# Uchip_regmap0 register map
File version: 1.0.0
Registers are 8-bit, read-write, reset 0x0 unless marked. A register's access mark holds for its fields unless they carry their own. Offsets are from the block's base; lines under a group give offsets from that group; [hi:lo] are bit positions; {n}, {i} and the like mark numbered series; 'fields as' and 'values as' point back to an identical list; <NAME> marks a mode.

## Memory map
0x00000000 CSR size 0x80

## CSR
Base 0x00000000
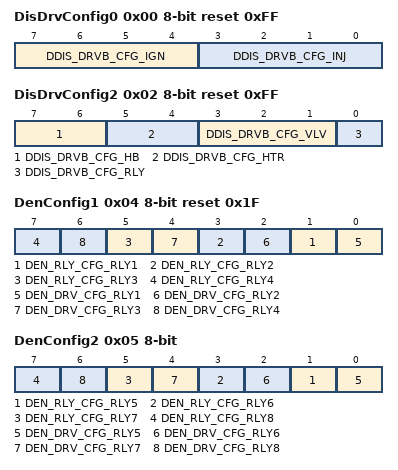
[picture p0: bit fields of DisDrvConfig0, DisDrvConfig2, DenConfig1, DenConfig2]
0x00 DisDrvConfig0 reset 0xFF — Настройка чувствительности силовых драйверов к DIS_DRVb - INJ[4:1], IGN[4:1]
  [7:4] DDIS_DRVB_CFG_IGN — Для IGN[4:1]: 0 - силовой драйвер не отключается при DIS_DRVb=0, 1 - силовой драйвер отключается при DIS_DRVb=0
  [3:0] DDIS_DRVB_CFG_INJ — Для INJ[4:1]: 0 - силовой драйвер не отключается при DIS_DRVb=0, 1 - силовой драйвер отключается при DIS_DRVb=0
0x01 DisDrvConfig1 reset 0xFF — Настройка чувствительности силовых драйверов к DIS_DRVb - RLY[8:1]
  [7:0] DDIS_DRVB_CFG_RLY — Для RLY[8:1]: 0 - силовой драйвер не отключается при DIS_DRVb=0 1 - силовой драйвер отключается при DIS_DRVb=0
0x02 DisDrvConfig2 reset 0xFF — Настройка чувствительности силовых драйверов к DIS_DRVb - RLY[9], VLV[3:1], HTR[2:1], HB[2:1]
  [7:6] DDIS_DRVB_CFG_HB — Для HB[2:1]: 0 - силовой драйвер не отключается при DIS_DRVb=0 1 - силовой драйвер отключается при DIS_DRVb=0
  [5:4] DDIS_DRVB_CFG_HTR — Для HTR[2:1]: 0 - силовой драйвер не отключается при DIS_DRVb=0 1 - силовой драйвер отключается при DIS_DRVb=0
  [3:1] DDIS_DRVB_CFG_VLV — Для VLV[3:1]: 0 - силовой драйвер не отключается при DIS_DRVb=0 1 - силовой драйвер отключается при DIS_DRVb=0
  [0] DDIS_DRVB_CFG_RLY — Для RLY[9]: 0 - силовой драйвер не отключается при DIS_DRVb=0 1 - силовой драйвер отключается при DIS_DRVb=0
0x03 DenConfig0 reset 0xF — Настройка чувствительности силовых драйверов к EN_DRV - IGN[4:1]
  [3:0] DEN_DRV_CFG_IGN — Для IGN[4:1]: 0 - силовой драйвер не отключается при EN_DRV=0 1 - силовой драйвер отключается при EN_DRV=0
0x04 DenConfig1 reset 0x1F — Настройка чувствительности силовых драйвер к EN_DRV и EN_RLY12 - RLY[4:1]
  [2n-1] DEN_RLY_CFG_RLY{n} (n=1..4) — Для RLY[{n}]: 0 - силовой драйвер не отключается при EN_RLY12=0 1 - силовой драйвер отключается при EN_RLY12=0
  [2n-2] DEN_DRV_CFG_RLY{n} (n=1..4) — Для RLY[{n}]: 0 - силовой драйвер не отключается при EN_DRV=0 1 - силовой драйвер отключается при EN_DRV=0
0x05 DenConfig2 — Настройка чувствительности силовых драйвер к EN_DRV и EN_RLY12 - RLY[8:5]
  [2n-9] DEN_RLY_CFG_RLY{n} (n=5..8) — Для RLY[{n}]: 0 - силовой драйвер не отключается при EN_RLY12=0 1 - силовой драйвер отключается при EN_RLY12=0
  [2n-10] DEN_DRV_CFG_RLY{n} (n=5..8) — Для RLY[{n}]: 0 - силовой драйвер не отключается при EN_DRV=0 1 - силовой драйвер отключается при EN_DRV=0
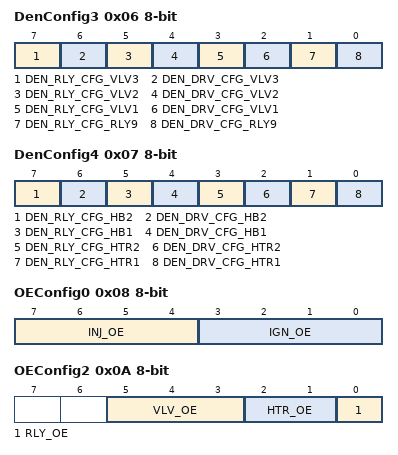
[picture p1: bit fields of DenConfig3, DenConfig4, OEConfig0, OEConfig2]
0x06 DenConfig3 — Настройка чувствительности силовых драйвер к EN_DRV и EN_RLY12 - RLY[9], VLV[3:1]
  [7] DEN_RLY_CFG_VLV3 — Для VLV[3]: 0 - силовой драйвер не отключается при EN_RLY12=0 1 - силовой драйвер отключается при EN_RLY12=0
  [6] DEN_DRV_CFG_VLV3 — Для VLV[3]: 0 - силовой драйвер не отключается при EN_DRV=0 1 - силовой драйвер отключается при EN_DRV=0
  [5] DEN_RLY_CFG_VLV2 — Для VLV[2]: 0 - силовой драйвер не отключается при EN_RLY12=0 1 - силовой драйвер отключается при EN_RLY12=0
  [4] DEN_DRV_CFG_VLV2 — Для VLV[2]: 0 - силовой драйвер не отключается при EN_DRV=0 1 - силовой драйвер отключается при EN_DRV=0
  [3] DEN_RLY_CFG_VLV1 — Для VLV[1]: 0 - силовой драйвер не отключается при EN_RLY12=0 1 - силовой драйвер отключается при EN_RLY12=0
  [2] DEN_DRV_CFG_VLV1 — Для VLV[1]: 0 - силовой драйвер не отключается при EN_DRV=0 1 - силовой драйвер отключается при EN_DRV=0
  [1] DEN_RLY_CFG_RLY9 — Для RLY[9]: 0 - силовой драйвер не отключается при EN_RLY12=0 1 - силовой драйвер отключается при EN_RLY12=0
  [0] DEN_DRV_CFG_RLY9 — Для RLY[9]: 0 - силовой драйвер не отключается при EN_DRV=0 1 - силовой драйвер отключается при EN_DRV=0
0x07 DenConfig4 — Настройка чувствительности силовых драйверов к EN_DRV и EN_RLY12 - HTR[2:1], HB[2:1]
  [7] DEN_RLY_CFG_HB2 — Для HB[2]: 0 - силовой драйвер не отключается при EN_RLY12=0 1 - силовой драйвер отключается при EN_RLY12=0
  [6] DEN_DRV_CFG_HB2 — Для HB[2]: 0 - силовой драйвер не отключается при EN_DRV=0 1 - силовой драйвер отключается при EN_DRV=0
  [5] DEN_RLY_CFG_HB1 — Для HB[1]: 0 - силовой драйвер не отключается при EN_RLY12=0 1 - силовой драйвер отключается при EN_RLY12=0
  [4] DEN_DRV_CFG_HB1 — Для HB[1]: 0 - силовой драйвер не отключается при EN_DRV=0 1 - силовой драйвер отключается при EN_DRV=0
  [3] DEN_RLY_CFG_HTR2 — Для HTR[2]: 0 - силовой драйвер не отключается при EN_RLY12=0 1 - силовой драйвер отключается при EN_RLY12=0
  [2] DEN_DRV_CFG_HTR2 — Для HTR[2]: 0 - силовой драйвер не отключается при EN_DRV=0 1 - силовой драйвер отключается при EN_DRV=0
  [1] DEN_RLY_CFG_HTR1 — Для HTR[1]: 0 - силовой драйвер не отключается при EN_RLY12=0 1 - силовой драйвер отключается при EN_RLY12=0
  [0] DEN_DRV_CFG_HTR1 — Для HTR[1]: 0 - силовой драйвер не отключается при EN_DRV=0 1 - силовой драйвер отключается при EN_DRV=0
0x08 OEConfig0 — Активация управления силовыми драйверами - IGN[4:1], INJ[4:1]
  [7:4] INJ_OE — Для INJ[4:1]: "0" - управление деактивировано "1" - управление активировано
  [3:0] IGN_OE — Для IGN[4:1]: 0 - управление деактивировано 1 - управление активировано
0x09 OEConfig1 — Активация управления силовыми драйверами - RLY[8:1]
  [7:0] RLY_OE — Для RLY[8:1]: 0 - управление деактивировано 1 - управление активировано
0x0A OEConfig2 — Активация управления силовыми драйверами - RLY[9], HTR[2:1], VLV[3:1]
  [5:3] VLV_OE — Для VLV[3:1]: 0 - управление деактивировано 1 - управление активировано
  [2:1] HTR_OE — Для HTR[2:1]: "0" - управление деактивировано "1" - управление активировано
  [0] RLY_OE — Для RLY[9]: 0 - управление деактивировано 1 - управление активировано
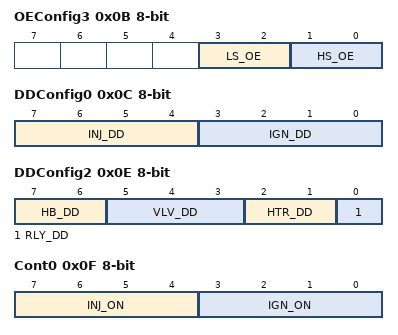
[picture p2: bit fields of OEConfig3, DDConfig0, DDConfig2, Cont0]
0x0B OEConfig3 — Активация\деактивация управления силовыми драйверами - HB[2:1]
  [3:2] LS_OE — Для LS[2:1]: 0 - управление деактивировано 1 - управление активировано
  [1:0] HS_OE — Для HS[2:1]: 0 - управление деактивировано 1 - управление активировано
0x0C DDConfig0 — Выбор способа управления силовыми драйверами - IGN[4:1], INJ[4:1]
  [7:4] INJ_DD — Для INJ[4:1]: 0 - управление осуществляется через SPI 1 - управление осуществляется через Входы Непосредственного Управления
  [3:0] IGN_DD — Для IGN[4:1]: 0 - управление осуществляется через SPI 1 - управление осуществляется через Входы Непосредственного Управления
0x0D DDConfig1 — Выбор способа управления силовыми драйверами - RLY[8:1]
  [7:0] RLY_DD — Для RLY[8:1]: 0 - управление осуществляется через SPI 1 - управление осуществляется через Входы Непосредственного Управления
0x0E DDConfig2 — Выбор способа управления силовыми драйверами - RLY[9], HTR[2:1], VLV[3:1], HB[2:1]
  [7:6] HB_DD — Для HB[2:1]: "0" - управление осуществляется через SPI "1" - управление осуществляется через Входы Непосредственного Управления
  [5:3] VLV_DD — Для VLV[3:1]: 0 - управление осуществляется через SPI 1 - управление осуществляется через Входы Непосредственного Управления
  [2:1] HTR_DD — Для HTR[2:1]: 0 - управление осуществляется через SPI 1 - управление осуществляется через Входы Непосредственного Управления
  [0] RLY_DD — Для RLY[9]: 0 - управление осуществляется через SPI 1 - управление осуществляется через Входы Непосредственного Управления
0x0F Cont0 — SPI-управление ctrl-сигналом силовых драйверов - IGN[4:1], INJ[4:1]
  [7:4] INJ_ON — Для INJ[4:1]: "0" - силовой драйвер ВЫКЛ. "1" - силовой драйвер ВКЛ.
  [3:0] IGN_ON — Для IGN[4:1]: 0 - силовой драйвер ВЫКЛ. 1 - силовой драйвер ВКЛ.
0x10 Cont1 — SPI-управление ctrl-сигналом силовых драйверов - RLY[8:1]
  [7:0] RLY_ON — Для RLY[8:1]: 0 - силовой драйвер ВЫКЛ. 1 - силовой драйвер ВКЛ.
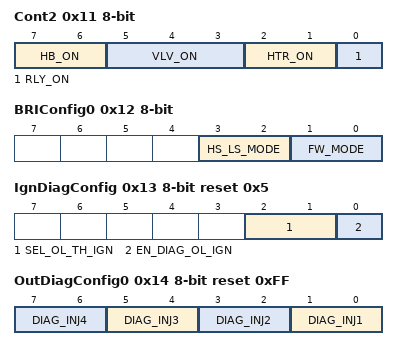
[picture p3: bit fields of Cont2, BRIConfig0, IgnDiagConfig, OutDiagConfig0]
0x11 Cont2 — SPI-управление ctrl-сигналом силовых драйверов - RLY[9], HTR[2:1], VLV[3:1], HB[2:1]
  [7:6] HB_ON — Для HB[2:1]: 0 - силовой драйвер ВЫКЛ. 1 - силовой драйвер ВКЛ.
  [5:3] VLV_ON — Для VLV[3:1]: 0 - силовой драйвер ВЫКЛ. 1 - силовой драйвер ВКЛ.
  [2:1] HTR_ON — Для HTR[2:1]: 0 - силовой драйвер ВЫКЛ. 1 - силовой драйвер ВКЛ.
  [0] RLY_ON — Для RLY[9]: 0 - силовой драйвер ВЫКЛ. 1 - силовой драйвер ВКЛ.
0x12 BRIConfig0 — Настройка работы полумостов - HB[2:1]
  [3:2] HS_LS_MODE — Настройка ctrl-сигнала для HB[2:1]: 0 - ctrl-сигнал идёт на LS 1 - ctrl-сигнал идёт на HS
  [1:0] FW_MODE — Режим Free Wheeling для HB[2:1]: 0 - ВЫКЛ. 1 - ВКЛ.
0x13 IgnDiagConfig reset 0x5 — Настройка OL-диагностики - IGN[4:1]
  [2:1] SEL_OL_TH_IGN — Настройка порога OL-диагностики
  [0] EN_DIAG_OL_IGN — Активация OL-диагностики: 0 - диагностика ВЫКЛ. 1 - диагностика ВКЛ.
0x14 OutDiagConfig0 reset 0xFF — Настройка конфигурации диагностик силовых драйверов - INJ[4:1]
  [2n-1:2n-2] DIAG_INJ{n} (n=1..4) — Для INJ[{n}]: 0x0 - все диагностики ВЫКЛ. 0x1 - все диагностики ВЫКЛ. 0x2 -только SCG/SCB диагностика ВКЛ. 0x3 - SCG/SCB и OL диагностика ВКЛ.
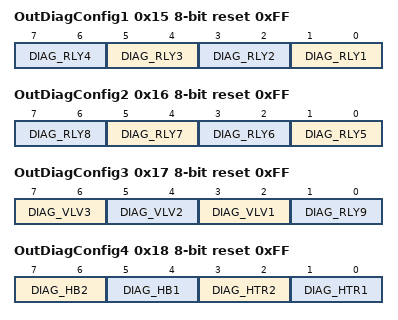
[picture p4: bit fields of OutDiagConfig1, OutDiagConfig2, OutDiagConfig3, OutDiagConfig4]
0x15 OutDiagConfig1 reset 0xFF — Настройка конфигурации диагностик силовых драйверов - RLY[4:1]
  [2n-1:2n-2] DIAG_RLY{n} (n=1..4) — Для RLY[{n}]: 0x0 - все диагностики ВЫКЛ. 0x1 - все диагностики ВЫКЛ. 0x2 -только SCG/SCB диагностика ВКЛ. 0x3 - SCG/SCB и OL диагностика ВКЛ.
0x16 OutDiagConfig2 reset 0xFF — Настройка конфигурации диагностик силовых драйверов - RLY[8:5]
  [2n-9:2n-10] DIAG_RLY{n} (n=5..8) — Для RLY[{n}]: 0x0 - все диагностики ВЫКЛ. 0x1 - все диагностики ВЫКЛ. 0x2 -только SCG/SCB диагностика ВКЛ. 0x3 - SCG/SCB и OL диагностика ВКЛ.
0x17 OutDiagConfig3 reset 0xFF — Настройка конфигурации диагностик силовых драйверов - RLY[9], VLV[3:1]
  [7:6] DIAG_VLV3 — Для VLV[3]: 0x0 - все диагностики ВЫКЛ. 0x1 - все диагностики ВЫКЛ. 0x2 -только SCG/SCB диагностика ВКЛ. 0x3 - SCG/SCB и OL диагностика ВКЛ.
  [5:4] DIAG_VLV2 — Для VLV[2]: 0x0 - все диагностики ВЫКЛ. 0x1 - все диагностики ВЫКЛ. 0x2 -только SCG/SCB диагностика ВКЛ. 0x3 - SCG/SCB и OL диагностика ВКЛ.
  [3:2] DIAG_VLV1 — Для VLV[1]: 0x0 - все диагностики ВЫКЛ. 0x1 - все диагностики ВЫКЛ. 0x2 -только SCG/SCB диагностика ВКЛ. 0x3 - SCG/SCB и OL диагностика ВКЛ.
  [1:0] DIAG_RLY9 — Для RLY[9]: 0x0 - все диагностики ВЫКЛ. 0x1 - все диагностики ВЫКЛ. 0x2 -только SCG/SCB диагностика ВКЛ. 0x3 - SCG/SCB и OL диагностика ВКЛ.
0x18 OutDiagConfig4 reset 0xFF — Настройка конфигурации диагностик силовых драйверов - HTR[2:1], HB[2:1]
  [7:6] DIAG_HB2 — Для HB[2]: 0x0 - все диагностики ВЫКЛ. 0x1 - все диагностики ВЫКЛ. 0x2 -только SCG/SCB диагностика ВКЛ. 0x3 - SCG/SCB и OL диагностика ВКЛ.
  [5:4] DIAG_HB1 — Для HB[1]: 0x0 - все диагностики ВЫКЛ. 0x1 - все диагностики ВЫКЛ. 0x2 -только SCG/SCB диагностика ВКЛ. 0x3 - SCG/SCB и OL диагностика ВКЛ.
  [3:2] DIAG_HTR2 — Для HTR[2]: 0x0 - все диагностики ВЫКЛ. 0x1 - все диагностики ВЫКЛ. 0x2 -только SCG/SCB диагностика ВКЛ. 0x3 - SCG/SCB и OL диагностика ВКЛ.
  [1:0] DIAG_HTR1 — Для HTR[1]: 0x0 - все диагностики ВЫКЛ. 0x1 - все диагностики ВЫКЛ. 0x2 -только SCG/SCB диагностика ВКЛ. 0x3 - SCG/SCB и OL диагностика ВКЛ.
0x19 CurrLimConfig0 — Активация режима ограничения по току силовых драйверов в случае OC - INJ[4:1]
  [3:0] CURR_LIM_INJ — Для INJ[4:1]: 0 - режим ВЫКЛ. 1 - режим ВКЛ.
0x1A CurrLimConfig1 — Активация режима ограничения по току силовых драйверов в случае OC - RLY[8:1]
  [7:0] CURR_LIM_RLY — Для RLY[8:1]: 0 - режим ВЫКЛ. 1 - режим ВКЛ.
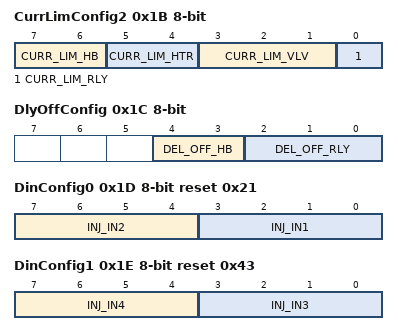
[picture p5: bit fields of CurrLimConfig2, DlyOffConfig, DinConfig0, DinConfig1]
0x1B CurrLimConfig2 — Активация режима ограничения по току силовых драйверов в случае OC - RLY[9], VLV[3:1], HTR[2:1], HB[2:1]
  [7:6] CURR_LIM_HB — Для HB[2:1]: 0 - режим ВЫКЛ. 1 - режим ВКЛ.
  [5:4] CURR_LIM_HTR — Для HTR[2:1]: 0 - режим ВЫКЛ. 1 - режим ВКЛ.
  [3:1] CURR_LIM_VLV — Для VLV[3:1]: 0 - режим ВЫКЛ. 1 - режим ВКЛ.
  [0] CURR_LIM_RLY — Для RLY[9]: 0 - режим ВЫКЛ. 1 - режим ВКЛ.
0x1C DlyOffConfig — Активация режима позднего отключения силовых драйверов в случае VDD5_UV, VDD5_OV, WD_FAIL, RSTb=0
  [4:3] DEL_OFF_HB — Для HB[2:1]: 0 - режим ВЫКЛ. 1 - режим ВКЛ.
  [2:0] DEL_OFF_RLY — Для RLY[3:1]: 0 - режим ВЫКЛ. 1 - режим ВКЛ.
0x1D DinConfig0 reset 0x21 — Выбор Входа Непосредственно Управления для управления силовыми драйверами - INJ[2:1]
  [7:4] INJ_IN2 — Для INJ[2]: 0x1 - IN1, 0x2 - IN2, 0x3 - IN3, 0x4 - IN4, 0x5 - IN5, 0x6 - IN6, 0x7 - IN7, 0x8 - IN8, 0x9 - IN9, 0xA - IN10, 0xB - IN11, 0xC - IN12, 0xD - IN13
  [3:0] INJ_IN1 — Для INJ[1]: 0x1 - IN1, 0x2 - IN2, 0x3 - IN3, 0x4 - IN4, 0x5 - IN5, 0x6 - IN6, 0x7 - IN7, 0x8 - IN8, 0x9 - IN9, 0xA - IN10, 0xB - IN11, 0xC - IN12, 0xD - IN13
0x1E DinConfig1 reset 0x43 — Выбор Входа Непосредственно Управления для управления силовыми драйверами - INJ[4:3]
  [7:4] INJ_IN4 — Для INJ[4]: 0x1 - IN1, 0x2 - IN2, 0x3 - IN3, 0x4 - IN4, 0x5 - IN5, 0x6 - IN6, 0x7 - IN7, 0x8 - IN8, 0x9 - IN9, 0xA - IN10, 0xB - IN11, 0xC - IN12, 0xD - IN13
  [3:0] INJ_IN3 — Для INJ[3]: 0x1 - IN1, 0x2 - IN2, 0x3 - IN3, 0x4 - IN4, 0x5 - IN5, 0x6 - IN6, 0x7 - IN7, 0x8 - IN8, 0x9 - IN9, 0xA - IN10, 0xB - IN11, 0xC - IN12, 0xD - IN13
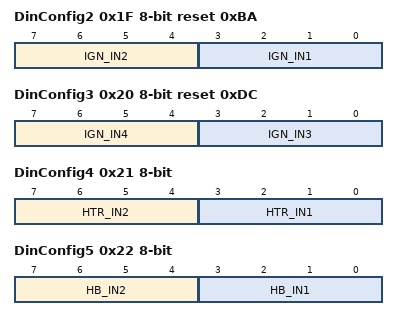
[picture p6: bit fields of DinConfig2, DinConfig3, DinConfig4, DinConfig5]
0x1F DinConfig2 reset 0xBA — Выбор Входа Непосредственно Управления для управления силовыми драйверами - IGN[2:1]
  [7:4] IGN_IN2 — Для IGN[2]: 0x1 - IN1, 0x2 - IN2, 0x3 - IN3, 0x4 - IN4, 0x5 - IN5, 0x6 - IN6, 0x7 - IN7, 0x8 - IN8, 0x9 - IN9, 0xA - IN10, 0xB - IN11, 0xC - IN12, 0xD - IN13
  [3:0] IGN_IN1 — Для IGN[1]: 0x1 - IN1, 0x2 - IN2, 0x3 - IN3, 0x4 - IN4, 0x5 - IN5, 0x6 - IN6, 0x7 - IN7, 0x8 - IN8, 0x9 - IN9, 0xA - IN10, 0xB - IN11, 0xC - IN12, 0xD - IN13
0x20 DinConfig3 reset 0xDC — Выбор Входа Непосредственно Управления для управления силовыми драйверами - IGN[4:3]
  [7:4] IGN_IN4 — Для IGN[4]: 0x1 - IN1, 0x2 - IN2, 0x3 - IN3, 0x4 - IN4, 0x5 - IN5, 0x6 - IN6, 0x7 - IN7, 0x8 - IN8, 0x9 - IN9, 0xA - IN10, 0xB - IN11, 0xC - IN12, 0xD - IN13
  [3:0] IGN_IN3 — Для IGN[3]: 0x1 - IN1, 0x2 - IN2, 0x3 - IN3, 0x4 - IN4, 0x5 - IN5, 0x6 - IN6, 0x7 - IN7, 0x8 - IN8, 0x9 - IN9, 0xA - IN10, 0xB - IN11, 0xC - IN12, 0xD - IN13
0x21 DinConfig4 — Выбор Входа Непосредственно Управления для управления силовыми драйверами - HTR[2:1]
  [7:4] HTR_IN2 — Для HTR[2]: 0x1 - IN1, 0x2 - IN2, 0x3 - IN3, 0x4 - IN4, 0x5 - IN5, 0x6 - IN6, 0x7 - IN7, 0x8 - IN8, 0x9 - IN9, 0xA - IN10, 0xB - IN11, 0xC - IN12, 0xD - IN13
  [3:0] HTR_IN1 — Для HTR[1]: 0x1 - IN1, 0x2 - IN2, 0x3 - IN3, 0x4 - IN4, 0x5 - IN5, 0x6 - IN6, 0x7 - IN7, 0x8 - IN8, 0x9 - IN9, 0xA - IN10, 0xB - IN11, 0xC - IN12, 0xD - IN13
0x22 DinConfig5 — Выбор Входа Непосредственно Управления для управления силовыми драйверами - HB[2:1]
  [7:4] HB_IN2 — Для HB[2]: 0x1 - IN1, 0x2 - IN2, 0x3 - IN3, 0x4 - IN4, 0x5 - IN5, 0x6 - IN6, 0x7 - IN7, 0x8 - IN8, 0x9 - IN9, 0xA - IN10, 0xB - IN11, 0xC - IN12, 0xD - IN13
  [3:0] HB_IN1 — Для HB[1]: 0x1 - IN1, 0x2 - IN2, 0x3 - IN3, 0x4 - IN4, 0x5 - IN5, 0x6 - IN6, 0x7 - IN7, 0x8 - IN8, 0x9 - IN9, 0xA - IN10, 0xB - IN11, 0xC - IN12, 0xD - IN13
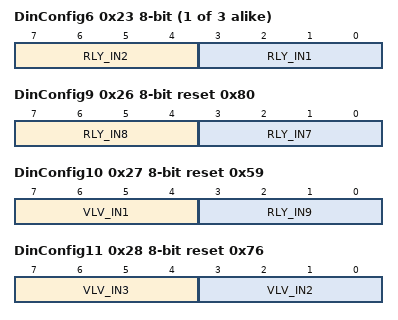
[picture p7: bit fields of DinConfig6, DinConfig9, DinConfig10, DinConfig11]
{0x1D+i} DinConfig{i} (i=6..8) — Выбор Входа Непосредственно Управления для управления силовыми драйверами - RLY[{2i-10}:{2i-11}]
  [7:4] RLY_IN{2i-10} — Для RLY[{2i-10}]: 0x1 - IN1, 0x2 - IN2, 0x3 - IN3, 0x4 - IN4, 0x5 - IN5, 0x6 - IN6, 0x7 - IN7, 0x8 - IN8, 0x9 - IN9, 0xA - IN10, 0xB - IN11, 0xC - IN12, 0xD - IN13
  [3:0] RLY_IN{2i-11} — Для RLY[{2i-11}]: 0x1 - IN1, 0x2 - IN2, 0x3 - IN3, 0x4 - IN4, 0x5 - IN5, 0x6 - IN6, 0x7 - IN7, 0x8 - IN8, 0x9 - IN9, 0xA - IN10, 0xB - IN11, 0xC - IN12, 0xD - IN13
0x26 DinConfig9 reset 0x80 — Выбор Входа Непосредственно Управления для управления силовыми драйверами - RLY[8:7]
  [7:4] RLY_IN8 — Для RLY[8]: 0x1 - IN1, 0x2 - IN2, 0x3 - IN3, 0x4 - IN4, 0x5 - IN5, 0x6 - IN6, 0x7 - IN7, 0x8 - IN8, 0x9 - IN9, 0xA - IN10, 0xB - IN11, 0xC - IN12, 0xD - IN13
  [3:0] RLY_IN7 — Для RLY[7]: 0x1 - IN1, 0x2 - IN2, 0x3 - IN3, 0x4 - IN4, 0x5 - IN5, 0x6 - IN6, 0x7 - IN7, 0x8 - IN8, 0x9 - IN9, 0xA - IN10, 0xB - IN11, 0xC - IN12, 0xD - IN13
0x27 DinConfig10 reset 0x59 — Выбор Входа Непосредственно Управления для управления силовыми драйверами - RLY[9], VLV[1]
  [7:4] VLV_IN1 — Для VLV[1]: 0x1 - IN1, 0x2 - IN2, 0x3 - IN3, 0x4 - IN4, 0x5 - IN5, 0x6 - IN6, 0x7 - IN7, 0x8 - IN8, 0x9 - IN9, 0xA - IN10, 0xB - IN11, 0xC - IN12, 0xD - IN13
  [3:0] RLY_IN9 — Для RLY[9]: 0x1 - IN1, 0x2 - IN2, 0x3 - IN3, 0x4 - IN4, 0x5 - IN5, 0x6 - IN6, 0x7 - IN7, 0x8 - IN8, 0x9 - IN9, 0xA - IN10, 0xB - IN11, 0xC - IN12, 0xD - IN13
0x28 DinConfig11 reset 0x76 — Выбор Входа Непосредственно Управления для управления силовыми драйверами - VLV[3:2]
  [7:4] VLV_IN3 — Для VLV[3]: 0x1 - IN1, 0x2 - IN2, 0x3 - IN3, 0x4 - IN4, 0x5 - IN5, 0x6 - IN6, 0x7 - IN7, 0x8 - IN8, 0x9 - IN9, 0xA - IN10, 0xB - IN11, 0xC - IN12, 0xD - IN13
  [3:0] VLV_IN2 — Для VLV[2]: 0x1 - IN1, 0x2 - IN2, 0x3 - IN3, 0x4 - IN4, 0x5 - IN5, 0x6 - IN6, 0x7 - IN7, 0x8 - IN8, 0x9 - IN9, 0xA - IN10, 0xB - IN11, 0xC - IN12, 0xD - IN13
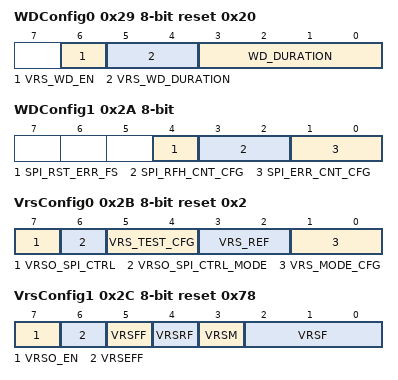
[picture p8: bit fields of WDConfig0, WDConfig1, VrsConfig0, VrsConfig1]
0x29 WDConfig0 reset 0x20 — Настройки Сторожевых Таймеров (WatchDog)
  [6] VRS_WD_EN — Активация VRS WatchDog: 0 - ВЫКЛ. 1 - ВКЛ.
  [5:4] VRS_WD_DURATION — Настройка порога VRS WatchDog
  [3:0] WD_DURATION — Настройка длительности ожидания "посылки-ответа" SPI WatchDog
0x2A WDConfig1 — Настройки SPI WatchDog
  [4] SPI_RST_ERR_FS — Настройка порога генерации FAULTb, RSTb: 0 - стандартный порог 1 - уменьшенный в два раза порог
  [3:2] SPI_RFH_CNT_CFG — Настройка порога счетчика успехов: 0x0 - 6 успехов 0x1 - 6 успехов 0x2 - 4 успеха 0x3 - 2 успеха
  [1:0] SPI_ERR_CNT_CFG — Настройка порога счетчика ошибок: 0x0 - 6 ошибок 0x1 - 6 ошибок 0x2 - 4 ошибки 0x3 - 2 ошибки
0x2B VrsConfig0 reset 0x2 — Конфигурация VR Сенсора
  [7] VRSO_SPI_CTRL — Сигнал установки значения на VRS_OUT в режиме прямого управления
  [6] VRSO_SPI_CTRL_MODE — Активация режима прямого управления управления VRS_OUT: 0 - ВЫКЛ. 1 - ВКЛ.
  [5:4] VRS_TEST_CFG — Настройка режима тестирования: 0x0 - все тесты 0x1 - SCG 0x2 - SCB 0x3 - OL
  [3:2] VRS_REF — Настройка значения vrs_ref
  [1:0] VRS_MODE_CFG — Настройка режима vrs_mode: 0x0 - ручной 0x1 - Hall-сенсор 0x2 - автоматический 0x3 - pre diag
0x2C VrsConfig1 reset 0x78 — Конфигурация VR Сенсора
  [7] VRSO_EN — Активация/деактивация VROUT-буфера: 0 - ВЫКЛ. 1 - ВКЛ.
  [6] VRSEFF — Активация/деактивация маскирования по Falling Edge: 0 - ВЫКЛ. 1 - ВКЛ.
  [5] VRSFF — Активация/деактивация фильтрации по Falling Edge: 0 - ВЫКЛ. 1 - ВКЛ.
  [4] VRSRF — Активация/деактивация фильтрации по Rising Edge: 0 - ВЫКЛ. 1 - ВКЛ.
  [3] VRSM — Настройка режима фильтации: 0 - адаптивный 1 - ручной
  [2:0] VRSF — Настройка времени фильтрации в ручном режиме: 0x0 - 2мкс 0x1 - 4мкс 0x2 - 8мкс 0x3 - 16мкс 0x4 - 32мкс 0x5 - 64мкс 0x6 - 128мкс 0x7 - 200мкс
0x2D VrsConfig2 — Конфигурация VR Сенсора
  [6:0] VRS_OL_DIAG — Настройка OL-диагностики VR Сенсора
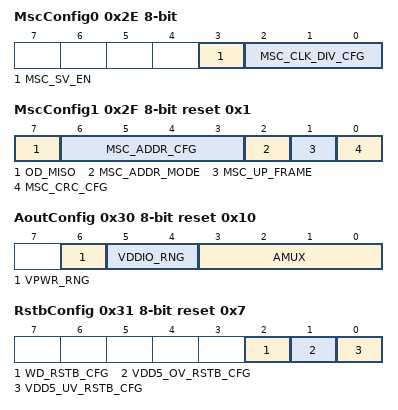
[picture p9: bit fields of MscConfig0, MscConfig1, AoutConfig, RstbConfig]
0x2E MscConfig0 — Конфигурация MSC Интерфейса
  [3] MSC_SV_EN — Активация/деактивация SuperVision функции: 0 - ВЫКЛ. 1 - ВКЛ.
  [2:0] MSC_CLK_DIV_CFG — Настройка делителя частоты SCLK для Upstream-посылок: 0x0 - 64 0x1 - 4 0x2 - 8 0x3 - 16 0x4 - 32 0x5 - 64 0x6 - 128 0x7 - 256
0x2F MscConfig1 reset 0x1 — Конфигурация MSC Интерфейса
  [7] OD_MISO — Активация режима OpenDrain для MSC: 0 - ВЫКЛ. 1 - ВКЛ.
  [6:3] MSC_ADDR_CFG — Значения адресного поля в случае выбора фиксированного адреса
  [2] MSC_ADDR_MODE — Активация режима установки адресного поля: 0 - автоматический подбор 1 - фиксированный MSC_ADDR_CFG
  [1] MSC_UP_FRAME — Настройка типа Upstream кадра: 0 - без адресного поля 1 - с адресным полем
  [0] MSC_CRC_CFG — Тип бита четности: 0 - нечётный 1 - чётный
0x30 AoutConfig reset 0x10 — Конфигурация AOUT буфера
  [6] VPWR_RNG — Настройка порогов VPWR-монитора: 0 - sel_vpwr_ov_th=0 - 12В 1 - sel_vpwr_ov_th=1 - 24В
  [5:4] VDDIO_RNG — Настройка порогов VDDIO-монитора: 0x0 - sel_vddio_uv_th=0, sel_vddio_ov_th=0 - 3.3В 0x1 - sel_vddio_uv_th=0, sel_vddio_ov_th=1 - широкий диапазон 0x2 - sel_vddio_uv_th=1, sel_vddio_ov_th=0 - узкий диапазон 0x3 - sel_vddio_uv_th=1, sel_vddio_ov_th=1 - 5В
  [3:0] AMUX — Настройка AOUT-буфера: 0x0 - en_aout=0 0x1 - en_aout=1, sel_aout_vrs_amp=1 - выводится дифф. напряжения усилителя VRS 0x2 - en_aout=1, sel_aout_vdd5_sns=1 - выводится VDD5 0x3 - en_aout=1, sel_aout_vddio_sns=1 - выводится VDDIO 0x4 - en_aout=1, sel_aout_vpwr_sns=1 - выводится VPWR 0x5 - en_aout=1, sel_aout_vtemp_sns=1 - выводится напряжения температурного датчика any: en_aout=0
0x31 RstbConfig reset 0x7 — Конфигурация сброса цифровой логики
  [2] WD_RSTB_CFG — Сброс цифрвой логики по переполнению WD счетчика ошибок: 0 - reset не происходит 1 - reset происходит
  [1] VDD5_OV_RSTB_CFG — Сброс цифрвой логики по VDD5_OV: 0 - reset не происходит 1 - reset происходит
  [0] VDD5_UV_RSTB_CFG — Сброс цифррвой логики по VDD5_UV: 0 - reset не происходит 1 - reset происходит
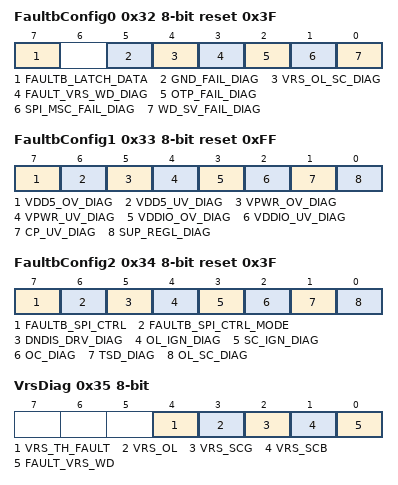
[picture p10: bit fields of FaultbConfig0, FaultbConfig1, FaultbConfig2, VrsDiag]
0x32 FaultbConfig0 reset 0x3F — Конфигурация FAULTb вывода
  [7] FAULTB_LATCH_DATA — Режим репортирования ошибок: 0 - репортируются актуальные ошибки 1 - репортируются ошибки, хранящиеся в диагностических регистрах
  [5] GND_FAIL_DIAG — Настройка реакции FAULTb на ошибки потери земли (AGND/PGND/GNDIO_LOSS): 0 - игнорирурет 1 - репортирует
  [4] VRS_OL_SC_DIAG — Настройка реакции FAULTb на ошибки диагностик VRS (OL, SCG, SCB): 0 - игнорирурет 1 - репортирует
  [3] FAULT_VRS_WD_DIAG — Настройка реакции FAULTb на ошибку по VRS WD: 0 - игнорирурет 1 - репортирует
  [2] OTP_FAIL_DIAG — Настройка реакции FAULTb на OTP-ошибку (ошибка коммуникации OTP, обращение к занятому контроллеру, ошибка чтения OTP, ошибка tm тестов margin off, margin1, margin2, selftest): 0 - игнорирурет 1 - репортирует
  [1] SPI_MSC_FAIL_DIAG — Настройка реакции FAULTb на обращения по SPI/MSC к неверному адресу: 0 - игнорирурет 1 - репортирует
  [0] WD_SV_FAIL_DIAG — Настройка реакции FAULTb на ошибки по WD и SV функциям: 0 - игнорирурет 1 - репортирует
0x33 FaultbConfig1 reset 0xFF — Конфигурация FAULTb вывода
  [7] VDD5_OV_DIAG — Настройка реакции FAULTb на OV по VDD5: 0 - игнорирурет 1 - репортирует
  [6] VDD5_UV_DIAG — Настройка реакции FAULTb на UV по VDD5: 0 - игнорирурет 1 - репортирует
  [5] VPWR_OV_DIAG — Настройка реакции FAULTb на OV по VPWR: 0 - игнорирурет 1 - репортирует
  [4] VPWR_UV_DIAG — Настройка реакции FAULTb на UV по VPWR: 0 - игнорирурет 1 - репортирует
  [3] VDDIO_OV_DIAG — Настройка реакции FAULTb на OV по VDDIO: 0 - игнорирурет 1 - репортирует
  [2] VDDIO_UV_DIAG — Настройка реакции FAULTb на UV по VDDIO: 0 - игнорирурет 1 - репортирует
  [1] CP_UV_DIAG — Настройка реакции FAULTb на UV по CP: 0 - игнорирурет 1 - репортирует
  [0] SUP_REGL_DIAG — Настройка реакции FAULTb на OV/UV по vdig_1p5v, vana_1p5v: 0 - игнорирурет 1 - репортирует
0x34 FaultbConfig2 reset 0x3F — Конфигурация FAULTb вывода
  [7] FAULTB_SPI_CTRL — Значение сигнала FAULTb в случае прямого управления
  [6] FAULTB_SPI_CTRL_MODE — Активация/деактивация режима прямого управления FAULTb: 0 - прямое управление ВЫКЛ. 1 - прямое управление ВКЛ.
  [5] DNDIS_DRV_DIAG — Настройка реакции FAULTb на DIS_DRVb=0: 0 - игнорирурет 1 - репортирует
  [4] OL_IGN_DIAG — Настройка реакции FAULTb на ошибки OL-диагностики для IGN: 0 - игнорирурет 1 - репортирует
  [3] SC_IGN_DIAG — Настройка реакции FAULTb на ошибки SCG/SCB-защиты для IGN: 0 - игнорирурет 1 - репортирует
  [2] OC_DIAG — Настройка реакции FAULTb на ошибки OC-защиты для RLY/INJ/VLV/HTR/HB: 0 - игнорирурет 1 - репортирует
  [1] TSD_DIAG — Настройка реакции FAULTb на ошибки TSD-защиты для RLY/INJ/VLV/HTR/HB/IGN: 0 - игнорирурет 1 - репортирует
  [0] OL_SC_DIAG — Настройка реакции FAULTb на ошибки OL-диагностик для RLY/INJ/VLV/HTR/HB, SCG-диагностик для RLY/INJ/VLV/HTR/HB_LS, SCB-диагностики для HB_HS: 0 - игнорирурет 1 - репортирует
0x35 VrsDiag ro — Диагностический регистр для VR Сенсора
  [4] VRS_TH_FAULT — Нарушение порога компаратора
  [3] VRS_OL — Обрыв нагрузки
  [2] VRS_SCG — КЗ на землю
  [1] VRS_SCB — КЗ на питание
  [0] FAULT_VRS_WD — Многоскратный сбой по VRS WD
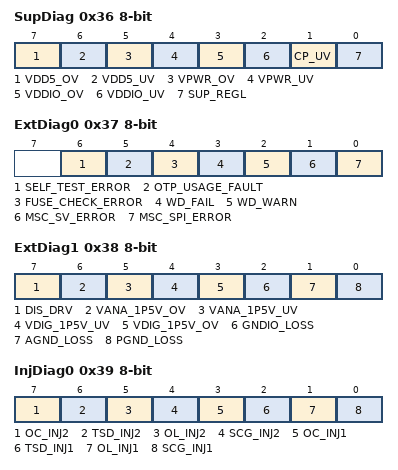
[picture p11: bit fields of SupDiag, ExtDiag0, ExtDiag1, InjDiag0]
0x36 SupDiag ro — Диагностический регистр для Мониторов питаний
  [7] VDD5_OV — OverVoltage по VDD5
  [6] VDD5_UV — UnderVoltage по VDD5
  [5] VPWR_OV — OverVoltage по VPWR
  [4] VPWR_UV — UnderVoltage по VPWR
  [3] VDDIO_OV — OverVoltage по VDDIO
  [2] VDDIO_UV — UnderVoltage по VDDIO
  [1] CP_UV — UnderVoltage по CP
  [0] SUP_REGL — Нарушения по vana_1p5v, vdig_1p5v (см. регистр ExtDiag1)
0x37 ExtDiag0 ro — Диагностический регистр внутренних ошибок цифровых функций
  [6] SELF_TEST_ERROR — Ошибка сравнения данных при тестовых проверках (margin off, margine1, margin2, selftest)
  [5] OTP_USAGE_FAULT — Обращение к занятомму контроллеру или неправльная команда OTP контроллера
  [4] FUSE_CHECK_ERROR — При чтении OTP обнаружены неверные данные
  [3] WD_FAIL — Исчерпан лимит ошибок по WD
  [2] WD_WARN — Предупреждение о наличии множественных нарушений по WD
  [1] MSC_SV_ERROR — Ошибка истечения SuperVision таймера
  [0] MSC_SPI_ERROR — Ошибка обращения по SPI/MSC к неверному адресу
0x38 ExtDiag1 ro — Диагностический регистр внутренних ошибок - потеря земли, OV/UV внутренних регуляторов
  [7] DIS_DRV — Статус DIS_DRVb=0
  [6] VANA_1P5V_OV — Ошибка OverVoltage по vana_1p5v
  [5] VANA_1P5V_UV — Ошибка UnderVoltage по vana_1p5v
  [4] VDIG_1P5V_UV — Ошибка UnderVoltage по vdig_1p5v
  [3] VDIG_1P5V_OV — Ошибка OverVoltage по vdig_1p5v
  [2] GNDIO_LOSS — Ошибка обрыва земли GNDIO
  [1] AGND_LOSS — Ошибка обрыва земли AGND
  [0] PGND_LOSS — Ошибка обрыва земли PGND
0x39 InjDiag0 ro — Диагностический регистр для силовых драйверов - INJ[2:1]
  [7] OC_INJ2 — OC для INJ[2]
  [6] TSD_INJ2 — TSD для INJ[2]
  [5] OL_INJ2 — OL для INJ[2]
  [4] SCG_INJ2 — SCG для INJ[2]
  [3] OC_INJ1 — OC для INJ[1]
  [2] TSD_INJ1 — TSD для INJ[1]
  [1] OL_INJ1 — OL для INJ[1]
  [0] SCG_INJ1 — SCG для INJ[1]
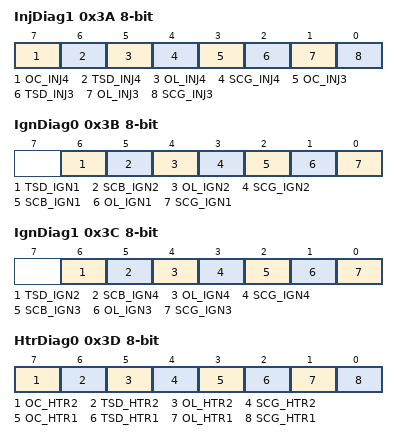
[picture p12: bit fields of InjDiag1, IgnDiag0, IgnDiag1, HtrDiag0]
0x3A InjDiag1 ro — Диагностический регистр для силовых драйверов - INJ[4:3]
  [7] OC_INJ4 — OC для INJ[4]
  [6] TSD_INJ4 — TSD для INJ[4]
  [5] OL_INJ4 — OL для INJ[4]
  [4] SCG_INJ4 — SCG для INJ[4]
  [3] OC_INJ3 — OC для INJ[3]
  [2] TSD_INJ3 — TSD для INJ[3]
  [1] OL_INJ3 — OL для INJ[3]
  [0] SCG_INJ3 — SCG для INJ[3]
0x3B IgnDiag0 ro — Диагностический регистр для силовых драйверов - IGN[2:1]
  [6] TSD_IGN1 — TSD для IGN[1:2]
  [5] SCB_IGN2 — SCB для IGN[2]
  [4] OL_IGN2 — OL для IGN[2]
  [3] SCG_IGN2 — SCG для IGN[2]
  [2] SCB_IGN1 — SCB для IGN[1]
  [1] OL_IGN1 — OL для IGN[1]
  [0] SCG_IGN1 — SCG для IGN[1]
0x3C IgnDiag1 ro — Диагностический регистр для силовых драйверов - IGN[4:3]
  [6] TSD_IGN2 — TSD для IGN[3:4]
  [5] SCB_IGN4 — SCB для IGN[4]
  [4] OL_IGN4 — OL для IGN[4]
  [3] SCG_IGN4 — SCG для IGN[4]
  [2] SCB_IGN3 — SCB для IGN[3]
  [1] OL_IGN3 — OL для IGN[3]
  [0] SCG_IGN3 — SCG для IGN[3]
0x3D HtrDiag0 ro — Диагностический регистр для силовых драйверов - HTR[2:1]
  [7] OC_HTR2 — OC для HTR[2]
  [6] TSD_HTR2 — TSD для HTR[2]
  [5] OL_HTR2 — OL для HTR[2]
  [4] SCG_HTR2 — SCG для HTR[2]
  [3] OC_HTR1 — OC для HTR[1]
  [2] TSD_HTR1 — TSD для HTR[1]
  [1] OL_HTR1 — OL для HTR[1]
  [0] SCG_HTR1 — SCG для HTR[1]
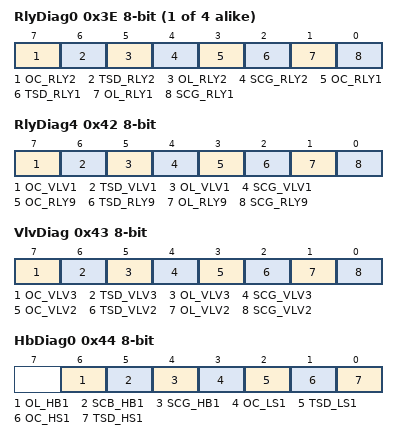
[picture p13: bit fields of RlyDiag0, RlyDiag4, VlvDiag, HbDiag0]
{0x3E+i} RlyDiag{i} ro (i=0..3) — Диагностический регистр для силовых драйверов - RLY[{2i+2}:{2i+1}]
  [7] OC_RLY{2i+2} — OC для RLY[{2i+2}]
  [6] TSD_RLY{2i+2} — TSD для RLY[{2i+2}]
  [5] OL_RLY{2i+2} — OL для RLY[{2i+2}]
  [4] SCG_RLY{2i+2} — SCG для RLY[{2i+2}]
  [3] OC_RLY{2i+1} — OC для RLY[{2i+1}]
  [2] TSD_RLY{2i+1} — TSD для RLY[{2i+1}]
  [1] OL_RLY{2i+1} — OL для RLY[{2i+1}]
  [0] SCG_RLY{2i+1} — SCG для RLY[{2i+1}]
0x42 RlyDiag4 ro — Диагностический регистр для силовых драйверов - RLY[9], VLV[1]
  [7] OC_VLV1 — OC для VLV[1]
  [6] TSD_VLV1 — TSD для VLV[1]
  [5] OL_VLV1 — OL для VLV[1]
  [4] SCG_VLV1 — SCG для VLV[1]
  [3] OC_RLY9 — OC для RLY[9]
  [2] TSD_RLY9 — TSD для RLY[9]
  [1] OL_RLY9 — OL для RLY[9]
  [0] SCG_RLY9 — SCG для RLY[9]
0x43 VlvDiag ro — Диагностический регистр для силовых драйверов - VLV[3:2]
  [7] OC_VLV3 — OC для VLV[3]
  [6] TSD_VLV3 — TSD для VLV[3]
  [5] OL_VLV3 — OL для VLV[3]
  [4] SCG_VLV3 — SCG для VLV[3]
  [3] OC_VLV2 — OC для VLV[2]
  [2] TSD_VLV2 — TSD для VLV[2]
  [1] OL_VLV2 — OL для VLV[2]
  [0] SCG_VLV2 — SCG для VLV[2]
0x44 HbDiag0 ro — Диагностический регистр для силовых драйверов - HB[1]
  [6] OL_HB1 — OL для HB[1]
  [5] SCB_HB1 — SCB для HB[1]
  [4] SCG_HB1 — SCG для HB[1]
  [3] OC_LS1 — OC для HB_LS[1]
  [2] TSD_LS1 — TSD для HB_LS[1]
  [1] OC_HS1 — OC для HB_HS[1]
  [0] TSD_HS1 — TSD для HB_HS[1]
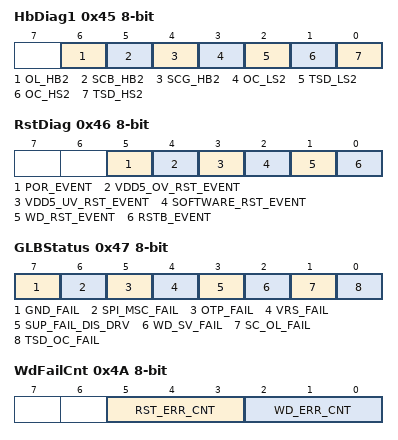
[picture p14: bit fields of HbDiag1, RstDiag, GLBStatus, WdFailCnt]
0x45 HbDiag1 ro — Диагностический регистр для силовых драйверов - HB[2]
  [6] OL_HB2 — OL для HB[2]
  [5] SCB_HB2 — SCB для HB[2]
  [4] SCG_HB2 — SCG для HB[2]
  [3] OC_LS2 — OC для HB_LS[2]
  [2] TSD_LS2 — TSD для HB_LS[2]
  [1] OC_HS2 — OC для HB_HS[2]
  [0] TSD_HS2 — TSD для HB_HS[2]
0x46 RstDiag ro — Статус причины сброса (reset) цифровой логики
  [5] POR_EVENT — Происходил сброс по PoR (отключение внутреннего 1.8В питания)
  [4] VDD5_OV_RST_EVENT — OverColtage по VDD5
  [3] VDD5_UV_RST_EVENT — UnderVoltage по VDD5
  [2] SOFTWARE_RST_EVENT — Была оправлена SPI/MSC команда на сброс
  [1] WD_RST_EVENT — Многократный сбой по WD
  [0] RSTB_EVENT — Порт RSTb переводили в 0
0x47 GLBStatus ro — Общий диагностический регистр цифровых функций
  [7] GND_FAIL — Потеря земли (PGND_LOSS/AGND_LOSS/GNDIO_LOSS)
  [6] SPI_MSC_FAIL — Ошибка коммуникации SPI/MSC
  [5] OTP_FAIL — Ошибка в блоке VR Сенсора (OL/SCG/SCB/VRS WD)
  [4] VRS_FAIL — Одно и более нарушений по питаниям VDD5, VPWR, vdig_1p5v, vana_1p5v
  [3] SUP_FAIL_DIS_DRV — Нарушение по WD или MSC SV
  [2] WD_SV_FAIL — Ошибка SCB/SCG/OL на одном или нескольких силовых транзисторах
  [1] SC_OL_FAIL — Ошибка OC/TSD на одном или нескольких силовых транзисторах
  [0] TSD_OC_FAIL — Ошибка в работе OTP (OTP_COMMUN_FAIL/OTP_USAGE_FAULT/FUSE_CHECK_ERROR/SELF_TEST_ERROR)
0x48 WdQuestion ro — Статус актуального вопроса WD
  [7:0] LFSR
0x49 WdPassCnt ro — Статус refresh-счётчика WD
  [2:0] WD_RFH_CNT
0x4A WdFailCnt ro — Статус счётчика ошибок и reset-счёстчика WD
  [5:3] RST_ERR_CNT — Статус reset-счётчика
  [2:0] WD_ERR_CNT — Статус счётчика ошибок
0x4B PSState0 ro — Статусный регистр выходов силовых драйверов - IGN[4:1], INJ[4:1]
  [7:4] OUT_STATE_INJ — Для INJ[4:1]
  [3:0] OUT_STATE_IGN — Для IGN[4:1]
0x4C PSState1 ro — Статусный регистр выходов силовых драйверов - RLY[8:1]
  [7:0] OUT_STATE_RLY — Для RLY[8:1]
0x4D PSState2 ro — Статусный регистр выходов силовых драйверов - RLY[9], HTR[2:1], VLV[3:1]
  [5:3] OUT_STATE_VLV — Для VLV[3:1]
  [2:1] OUT_STATE_HTR — Для HTR[2:1]
  [0] OUT_STATE_RLY — Для RLY[9]
0x4E PSState3 ro — Статусный регистр выходов силовых драйверов - HB[2:1]
  [3:2] OUT_STATE_LS — Для HB_LS[2:1]
  [1:0] OUT_STATE_HS — Для HB_HS[2:1]
0x4F InState0 ro — Статусный регистр входов Непосредственного Управления - IN[8:1]
  [7:0] DIN — Для IN[8:1]
0x50 InState1 ro — Статусный регистр входов Непосредственного Управления - IN[13:9]
  [4:0] DIN — Для IN[13:9]
0x51 EnState0 ro — Статусный регистр цифровых входов и глобальной команды OE
  [3] DNDIS_DRV — Статус входы DIS_DRVb
  [2] DEN_DRV — Статус входа EN_DRV
  [1] DEN_RLY — Статус входа EN_RLY12
  [0] OE — Статус глобальной команды OE
0x52 MaskID ro — Mask ID статус
  [4:0] MASK_ID
0x53 Cmd0 wo — Общие команды управления
  [7:0] Code — 0x0 - комманда блокировки управления всех силовых транзисторов (все OE=0) 0x1 - комманда на активацию управления всех силовых транзисторов (все OE=1) 0x2 - комманда на блокировку частотной модуляции осцилятора CP 0x3 - комманда на активацию частотной модуляции осцилятора CP 0x4 - комманда на старт диагностики VRS 0x5 - комманда на прерывание MSC UPSTREAM посылки 0x6 - комманда на сброс DELAY OFF таймера
0x54 CmdWdCheck wo — Посылка-ответ от MCU для WD
  [7:0] MCU_REPLY
0x55 CmdWdLdSd wo — Настройка WD вопроса
  [7:0] SEED — Стартовый seed для полинома WD
0x56 CmdSoftRst wo — Команда с кодовыми посылками для активации soft-reset
  [7:0] SOFTWARE_RST — 1 - data[7:0]=0xA3, 2 - data[7:0]=0x8F
0x57 MscRCmd0 wo — Настройка байта MSC Multiread посылки
  [n+3] DenConfig{n} (n=0..4), [2] DisDrvConfig2, [1] DisDrvConfig1, [0] DisDrvConfig0
0x58 MscRCmd1 wo — Настройка байта MSC Multiread посылки
  [6] Cont2, [5] Cont1, [4] Cont0, [n] OEConfig{n} (n=0..3)
0x59 MscRCmd2 wo — Настройка байта MSC Multiread посылки
  [7] CurrLimConfig2, [6] CurrLimConfig1, [5] CurrLimConfig0, [4] DlyOffConfig, [3] BRIConfig, [2] DDConfig2, [1] DDConfig1, [0] DDConfig0
0x5A MscRCmd3 wo — Настройка байта MSC Multiread посылки
  [5] IgnDiagConfig, [n] OutDiagConfig{n} (n=0..4)
0x5B MscRCmd4 wo — Настройка байта MSC Multiread посылки
  [n] DinConfig{n} (n=0..7)
0x5C MscRCmd5 wo — Настройка байта MSC Multiread посылки
  [7] FaultbConfig2, [6] FaultbConfig1, [5] FaultbConfig0, [4] RstbConfig, [n-8] DinConfig{n} (n=8..11)
0x5D MscRCmd6 wo — Настройка байта MSC Multiread посылки
  [7] AoutConfig, [6] MscConfig1, [5] MscConfig0, [4] VrsConfig2, [3] VrsConfig1, [2] VrsConfig0, [1] WDConfig1, [0] WDConfig0
0x5E MscRCmd7 wo — Настройка байта MSC Multiread посылки
  [3] ExtDiag1, [2] ExtDiag0, [1] SupDiag, [0] VrsDiag
0x5F MscRCmd8 wo — Настройка байта MSC Multiread посылки
  [5] HbDiag1, [4] HbDiag0, [3] IgnDiag1, [2] IgnDiag0, [1] InjDiag1, [0] InjDiag0
0x60 MscRCmd9 wo — Настройка байта MSC Multiread посылки
  [7] RstDiag, [6] VlvDiag, [5] HtrDiag0, [n] RlyDiag{n} (n=0..4)
0x61 MscRCmd10 wo — Настройка байта MSC Multiread посылки
  [3] WdFailCnt, [2] WdPassCnt, [1] WdQuestion, [0] GLBStatus
0x62 MscRCmd11 wo — Настройка байта MSC Multiread посылки
  [7] MaskId, [6] EnState0, [5] InState1, [4] InState0, [n] PSState{n} (n=0..3)
0x7D CmdSpecialMode — Активация специальных режимов - запись 8-битной кодовой посылки
  [7] SM_DIS_IGN_SCG_GNDLOSS — Чтение бита вернёт статус специального режима: 0 - режим ВЫКЛ. 1 - режим ВКЛ.
  [6] SM_DIS_OC — Чтение бита вернёт статус специального режима: 0 - режим ВЫКЛ. 1 - режим ВКЛ.
  [5] SM_DIS_VCP_UV — Чтение бита вернёт статус специального режима: 0 - режим ВЫКЛ. 1 - режим ВКЛ.
  [4] SM_DIS_VPWR_UV — Чтение бита вернёт статус специального режима: 0 - режим ВЫКЛ. 1 - режим ВКЛ.
  [3] SM_DIS_VPWR_OV — Чтение бита вернёт статус специального режима: 0 - режим ВЫКЛ. 1 - режим ВКЛ.
  [2] SM_DIS_VDD5_OV — Чтение бита вернёт статус специального режима: 0 - режим ВЫКЛ. 1 - режим ВКЛ.
  [1] SM_DIS_VDD5_UV — Чтение бита вернёт статус специального режима: 0 - режим ВЫКЛ. 1 - режим ВКЛ.
  [0] SM_DIS_TSD — Чтение бита вернёт статус специального режима: 0 - режим ВЫКЛ. 1 - режим ВКЛ.
0x7E CmdTM wo — Команда с кодовыми посылками для активации тестового режима
  [7:0] TM_CODE
0x7F PageVrb — Команда с кодовой посылкой для переключения страницы карты регистров
  [7:0] CODE — Запись или Чтение: Запись (W) - команда переключения страницы Чтение (R) - статус (бит 0 - номер активной страницы, бит 1 - статус testmode, бит 2 - статус special_mode, бит 3 - статус trim_mask)
